# STM32C031 register map
File version: 1.4
CPU: CM0 r0p0, little endian, MPU, FPU, 4 interrupt priority bits
Registers are 32-bit, read-write, reset 0x0 unless marked. A register's access mark holds for its fields unless they carry their own. Offsets are from the block's base; [hi:lo] are bit positions; {n}, {i} and the like mark numbered series.

## PWR — PWR address block description
Base 0x40007000
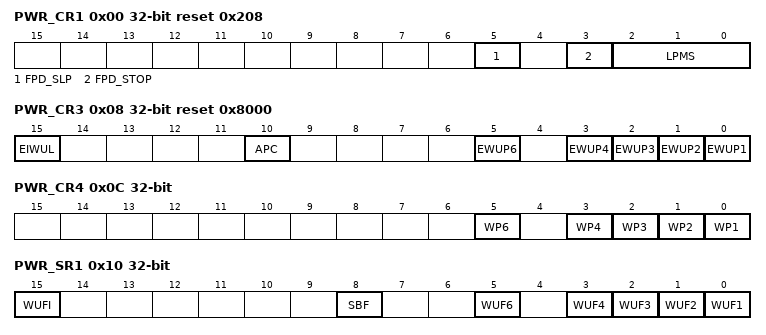
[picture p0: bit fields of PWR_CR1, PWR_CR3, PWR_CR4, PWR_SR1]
0x00 PWR_CR1 reset 0x208 — PWR control register 1
  [5] FPD_SLP — Flash memory powered down during Sleep mode This bit determines whether the Flash memory is put in power-down mode or remains in idle mode when the device enters Sleep mode.
    0=Flash memory idle; 1=Flash memory powered down
  [3] FPD_STOP — Flash memory powered down during Stop mode This bit determines whether the Flash memory is put in power-down mode or remains in idle mode when the device enters Stop mode.
    0=Flash memory idle; 1=Flash memory powered down
  [2:0] LPMS — Low-power mode selection These bits select the low-power mode entered when CPU enters deepsleep mode. 1XX: Shutdown mode
    0=Stop mode; 3=Standby mode
0x08 PWR_CR3 reset 0x8000 — PWR control register 3
  [15] EIWUL — Enable internal wakeup line When set, a rising edge on the internal wakeup line triggers a wakeup event.
    0=Disable; 1=Enable
  [10] APC — Apply pull-up and pull-down configuration This bit determines whether the I/O pull-up and pull-down configurations defined in the PWR_PUCRx and PWR_PDCRx registers are applied.
    0=Not applied; 1=Applied
  [5] EWUP6 — Enable WKUP6 wakeup pin When this bit is set, the WKUP6 external wakeup pin is enabled and triggers a wakeup event when a rising or a falling edge occurs. The active edge is configured through WP6 bit in the PWR_CR4 register.
  [3] EWUP4 — Enable WKUP4 wakeup pin When this bit is set, the WKUP4 external wakeup pin is enabled and triggers a wakeup event when a rising or a falling edge occurs. The active edge is configured via the WP4 bit in the PWR_CR4 register.
  [2] EWUP3 — Enable WKUP3 wakeup pin When this bit is set, the WKUP3 external wakeup pin is enabled and triggers a wakeup event when a rising or a falling edge occurs. The active edge is configured via the WP3 bit of the PWR_CR4 register.
  [1] EWUP2 — Enable WKUP2 wakeup pin When this bit is set, the WKUP2 external wakeup pin is enabled and triggers a wakeup event when a rising or a falling edge occurs. The active edge is configured via the WP2 bit of the PWR_CR4 register.
  [0] EWUP1 — Enable WKUP1 wakeup pin When this bit is set, the WKUP1 external wakeup pin is enabled and triggers a wakeup event when a rising or a falling edge occurs. The active edge is configured via the WP1 bit of the PWR_CR4 register.
0x0C PWR_CR4 — PWR control register 4
  [all] fields
    0=High level or rising edge; 1=Low level or falling edge
  [5] WP6 — WKUP6 wakeup pin polarity WKUP6 external wakeup signal polarity (level or edge) to generate wakeup condition:
  [n-1] WP{n} (n=1..4) — WKUP{n} wakeup pin polarity WKUP{n} external wakeup signal polarity (level or edge) to generate wakeup condition:
0x10 PWR_SR1 ro — PWR status register 1
  [15] WUFI — Wakeup flag internal This bit is set when a wakeup condition is detected on the internal wakeup line. It is cleared when all internal wakeup sources are cleared.
  [8] SBF — Standby/Shutdown flag This bit is set by hardware when the device enters Standby or Shutdown mode and is cleared by setting the CSBF bit in the PWR_SCR register, or by a power-on reset. It is not cleared by the system reset.
    0=The device did not enter Standby or Shutdown mode; 1=The device entered Standby or Shutdown mode
  [5] WUF6 — Wakeup flag 6 This bit is set when a wakeup condition is detected on WKUP6 wakeup pin. It is cleared by setting the CWUF6 bit of the PWR_SCR register.
  [n-1] WUF{n} (n=1..4) — Wakeup flag {n} This bit is set when a wakeup condition is detected on WKUP{n} wakeup pin. It is cleared by setting the CWUF{n} bit of the PWR_SCR register.
0x14 PWR_SR2 ro — PWR status register 2
  [7] FLASH_RDY — Flash ready flag This bit is set by hardware to indicate when the Flash memory is ready to be accessed after wakeup from power-down. To place the Flash memory in power-down, set either FPD_SLP or FPD_STP bit. Note: If the system boots from SRAM, the user application must wait till FLASH_RDY bit is set, prior to jumping to Flash memory.
    0=Flash memory in power-down; 1=Flash memory ready to be accessed
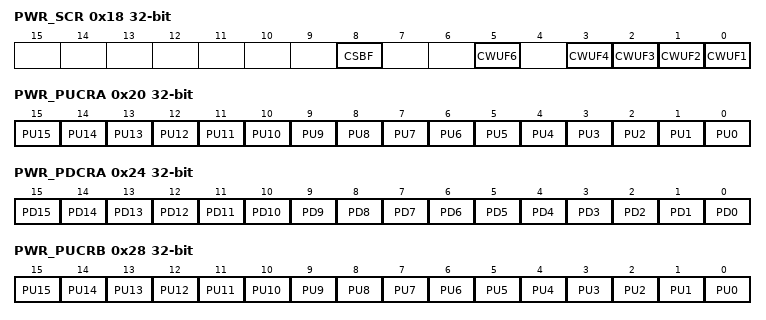
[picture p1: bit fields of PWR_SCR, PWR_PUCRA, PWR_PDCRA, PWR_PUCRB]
0x18 PWR_SCR wo — PWR status clear register
  [8] CSBF — Clear standby flag Setting this bit clears the SBF flag in the PWR_SR1 register.
  [5] CWUF6 — Clear wakeup flag 6 Setting this bit clears the WUF6 flag in the PWR_SR1 register.
  [n-1] CWUF{n} (n=1..4) — Clear wakeup flag {n} Setting this bit clears the WUF{n} flag in the PWR_SR1 register.
0x20 PWR_PUCRA — PWR Port A pull-up control register
  [n] PU{n} (n=0..15) — Port A pull-up bit i (i = 15 to 0) Setting PUi bit while the corresponding PDi bit is zero and the APC bit of the PWR_CR3 register is set activates a pull-up device on the PA[i] I/O.
0x24 PWR_PDCRA — PWR Port A pull-down control register
  [n] PD{n} (n=0..15) — Port A pull-down bit i (i = 15 to 0) Setting PDi bit while the APC bit of the PWR_CR3 register is set activates a pull-down device on the PA[i] I/O.
0x28 PWR_PUCRB — PWR Port B pull-up control register
  [n] PU{n} (n=0..15) — Port B pull-up bit i (i = 15 to 0) Setting PUi bit while the corresponding PDi bit is zero and the APC bit of the PWR_CR3 register is set activates a pull-up device on the PB[i] I/O. On STM32C011xx, only PU7 and PU6 are available
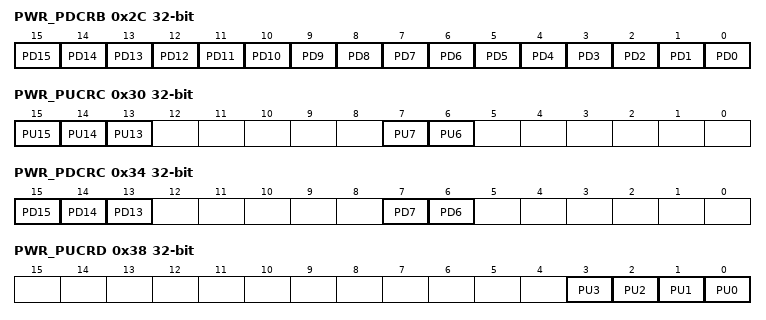
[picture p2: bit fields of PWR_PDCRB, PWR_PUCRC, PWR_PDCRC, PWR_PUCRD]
0x2C PWR_PDCRB — PWR Port B pull-down control register
  [n] PD{n} (n=0..15) — Port B pull-down bit i (i = 15 to 0) Setting PDi bit while the APC bit of the PWR_CR3 register is set activates a pull-down device on the PB[i] I/O. On STM32C011xx, only PD7 and PD6 are available
0x30 PWR_PUCRC — PWR Port C pull-up control register
  [15] PU15 — Port C pull-up bit i (i = 15 to 13, 7 to 6) Setting PUi bit while the corresponding PDi bit is zero and the APC bit of the PWR_CR3 register is set activates a pull-up device on the PC[i] I/O. On STM32C011xx, only PU15 and PU14 are available
  [14] PU14 — Port C pull-up bit i (i = 15 to 13, 7 to 6) Setting PUi bit while the corresponding PDi bit is zero and the APC bit of the PWR_CR3 register is set activates a pull-up device on the PC[i] I/O. On STM32C011xx, only PU15 and PU14 are available
  [13] PU13 — Port C pull-up bit i (i = 15 to 13, 7 to 6) Setting PUi bit while the corresponding PDi bit is zero and the APC bit of the PWR_CR3 register is set activates a pull-up device on the PC[i] I/O. On STM32C011xx, only PU15 and PU14 are available
  [7] PU7 — Port C pull-up bit i (i = 15 to 13, 7 to 6) Setting PUi bit while the corresponding PDi bit is zero and the APC bit of the PWR_CR3 register is set activates a pull-up device on the PC[i] I/O. On STM32C011xx, only PU15 and PU14 are available
  [6] PU6 — Port C pull-up bit i (i = 15 to 13, 7 to 6) Setting PUi bit while the corresponding PDi bit is zero and the APC bit of the PWR_CR3 register is set activates a pull-up device on the PC[i] I/O. On STM32C011xx, only PU15 and PU14 are available
0x34 PWR_PDCRC — PWR Port C pull-down control register
  [15] PD15 — Port C pull-down bit i (i = 15, 14, 13, 7, 6) Setting PDi bit while the APC bit of the PWR_CR3 register is set activates a pull-down device on the PC[i] I/O. On STM32C011xx, only PD15 and PD14 are available.
  [14] PD14 — Port C pull-down bit i (i = 15, 14, 13, 7, 6) Setting PDi bit while the APC bit of the PWR_CR3 register is set activates a pull-down device on the PC[i] I/O. On STM32C011xx, only PD15 and PD14 are available.
  [13] PD13 — Port C pull-down bit i (i = 15, 14, 13, 7, 6) Setting PDi bit while the APC bit of the PWR_CR3 register is set activates a pull-down device on the PC[i] I/O. On STM32C011xx, only PD15 and PD14 are available.
  [7] PD7 — Port C pull-down bit i (i = 15, 14, 13, 7, 6) Setting PDi bit while the APC bit of the PWR_CR3 register is set activates a pull-down device on the PC[i] I/O. On STM32C011xx, only PD15 and PD14 are available.
  [6] PD6 — Port C pull-down bit i (i = 15, 14, 13, 7, 6) Setting PDi bit while the APC bit of the PWR_CR3 register is set activates a pull-down device on the PC[i] I/O. On STM32C011xx, only PD15 and PD14 are available.
0x38 PWR_PUCRD — PWR Port D pull-up control register
  [n] PU{n} (n=0..3) — Port D pull-up bit i (i = 3 to 0) Setting PUi bit while the corresponding PDi bit is zero and the APC bit of the PWR_CR3 register is set activates a pull-up device on the PD[i] I/O.
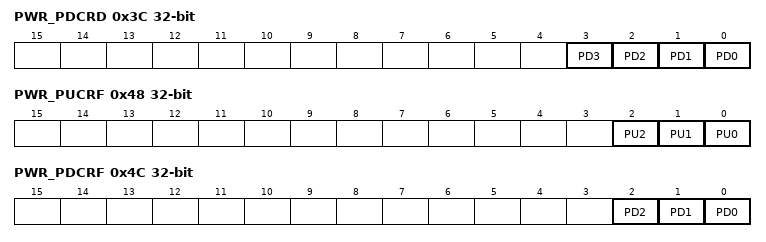
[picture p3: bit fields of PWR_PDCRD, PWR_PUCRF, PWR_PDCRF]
0x3C PWR_PDCRD — PWR Port D pull-down control register
  [n] PD{n} (n=0..3) — Port D pull-down bit i (i = 3 to 0) Setting PDi bit while the APC bit of the PWR_CR3 register is set activates a pull-down device on the PD[i] I/O.
0x48 PWR_PUCRF — PWR Port F pull-up control register
  [2] PU2 — Port F pull-up bit i (i = 2 to 0) Setting PUi bit while the corresponding PDi bit is zero and the APC bit of the PWR_CR3 register is set activates a pull-up device on the PF[i] I/O. On STM32C011xx, only PU2 is available.
  [1] PU1 — Port F pull-up bit i (i = 2 to 0) Setting PUi bit while the corresponding PDi bit is zero and the APC bit of the PWR_CR3 register is set activates a pull-up device on the PF[i] I/O. On STM32C011xx, only PU2 is available.
  [0] PU0 — Port F pull-up bit i (i = 2 to 0) Setting PUi bit while the corresponding PDi bit is zero and the APC bit of the PWR_CR3 register is set activates a pull-up device on the PF[i] I/O. On STM32C011xx, only PU2 is available.
0x4C PWR_PDCRF — PWR Port F pull-down control register
  [2] PD2 — Port F pull-down bit i (i = 2 to 0) Setting PDi bit while the APC bit of the PWR_CR3 register is set activates a pull-down device on the PF[i] I/O. On STM32C011xx, only PD2 is available.
  [1] PD1 — Port F pull-down bit i (i = 2 to 0) Setting PDi bit while the APC bit of the PWR_CR3 register is set activates a pull-down device on the PF[i] I/O. On STM32C011xx, only PD2 is available.
  [0] PD0 — Port F pull-down bit i (i = 2 to 0) Setting PDi bit while the APC bit of the PWR_CR3 register is set activates a pull-down device on the PF[i] I/O. On STM32C011xx, only PD2 is available.
